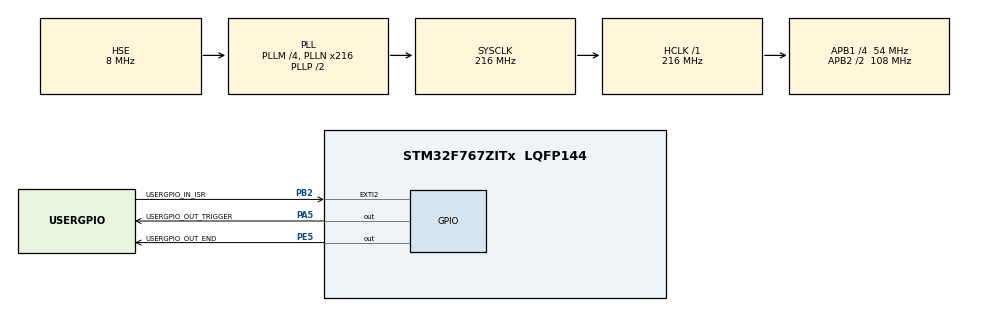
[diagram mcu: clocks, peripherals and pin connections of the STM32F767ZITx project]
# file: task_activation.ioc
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CORTEX_M7.ART_ACCELERATOR_ENABLE=0
CORTEX_M7.FlashInterface=TCM_Enabled
CORTEX_M7.PREFETCH_ENABLE=0
FREERTOS.BinarySemaphores01=semaphore,Dynamic,NULL
FREERTOS.Tasks01=Init,2,128,init,Default,NULL,Dynamic,NULL,NULL;_task1,0,128,task1,Default,NULL,Dynamic,NULL,NULL;_task2,1,128,task2,Default,NULL,Dynamic,NULL,NULL
Mcu.Family=STM32F7
Mcu.Name=STM32F767ZITx
Mcu.Package=LQFP144
NVIC.EXTI2_IRQn=true\:5\:0\:false\:false\:true\:true\:true\:true\:true
NVIC.PriorityGroup=NVIC_PRIORITYGROUP_4
NVIC.TIM6_DAC_IRQn=true\:15\:0\:false\:false\:true\:false\:false\:true\:true
NVIC.TimeBase=TIM6_DAC_IRQn
NVIC.TimeBaseIP=TIM6
PA13.GPIO_Label=TMS
PA13.Mode=Serial_Wire
PA13.Signal=SYS_JTMS-SWDIO
PA14.GPIO_Label=TCK
PA14.Mode=Serial_Wire
PA14.Signal=SYS_JTCK-SWCLK
PA5.GPIO_Label=USERGPIO_OUT_TRIGGER
PA5.GPIO_PuPd=GPIO_PULLDOWN
PA5.GPIO_Speed=GPIO_SPEED_FREQ_VERY_HIGH
PA5.Signal=GPIO_Output
PB2.GPIO_Label=USERGPIO_IN_ISR
PB2.Signal=GPXTI2
PE5.GPIO_Label=USERGPIO_OUT_END
PE5.GPIO_ModeDefaultOutputPP=GPIO_MODE_OUTPUT_PP
PE5.GPIO_PuPd=GPIO_PULLDOWN
PE5.GPIO_Speed=GPIO_SPEED_FREQ_VERY_HIGH
PE5.PinState=GPIO_PIN_RESET
PE5.Signal=GPIO_Output
PH0/OSC_IN.Mode=HSE-External-Oscillator
PH0/OSC_IN.Signal=RCC_OSC_IN
PH1/OSC_OUT.Mode=HSE-External-Oscillator
PH1/OSC_OUT.Signal=RCC_OSC_OUT
ProjectManager.HeapSize=0x200
ProjectManager.StackSize=0x400
ProjectManager.TargetToolchain=STM32CubeIDE
RCC.48MHZClocksFreq_Value=24000000
RCC.AHBFreq_Value=216000000
RCC.APB1CLKDivider=RCC_HCLK_DIV4
RCC.APB1Freq_Value=54000000
RCC.APB1TimFreq_Value=108000000
RCC.APB2CLKDivider=RCC_HCLK_DIV2
RCC.APB2Freq_Value=108000000
RCC.APB2TimFreq_Value=216000000
RCC.CortexFreq_Value=216000000
RCC.HCLKFreq_Value=216000000
RCC.HSE_VALUE=8000000
RCC.HSI_VALUE=16000000
RCC.LSE_VALUE=32768
RCC.PLLM=4
RCC.PLLMUL=RCC_PLL_MUL9
RCC.PLLN=216
RCC.PLLQ=9
RCC.PLLSourceVirtual=RCC_PLLSOURCE_HSE
RCC.PRESCALERUSB=RCC_USBCLKSOURCE_PLL_DIV1_5
RCC.SYSCLKFreq_VALUE=216000000
RCC.SYSCLKSource=RCC_SYSCLKSOURCE_PLLCLK
RCC.SYSCLKSourceVirtual=RCC_SYSCLKSOURCE_PLLCLK
RCC.USBFreq_Value=48000000
RCC.VCOOutputFreq_Value=432000000
VP_FREERTOS_VS_CMSIS_V1.Mode=CMSIS_V1
VP_SYS_VS_tim6.Mode=TIM6
board=NUCLEO-F767ZI

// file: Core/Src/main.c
/* USER CODE BEGIN Header */
/**
  ******************************************************************************
  * @file           : main.c
  * @brief          : Main program body
  ******************************************************************************
  * @attention
  *
  * Copyright (c) 2022 STMicroelectronics.
  * All rights reserved.
  *
  * This software is licensed under terms that can be found in the LICENSE file
  * in the root directory of this software component.
  * If no LICENSE file comes with this software, it is provided AS-IS.
  *
  ******************************************************************************
  */
/* USER CODE END Header */
#include "main.h"
#include "cmsis_os.h"

/* USER CODE BEGIN Includes */
#include "stdio.h"
#include <stdbool.h>
#include "FreeRTOS.h"

/* USER CODE END Includes */

/* USER CODE BEGIN PM */
#define TAKE_MEASUREMENT(x)     (x = DWT->CYCCNT)
#define NUM_SAMPLES             (1000)
/* USER CODE END PM */

osThreadId InitHandle;
osThreadId _task1Handle;
osThreadId _task2Handle;
osSemaphoreId semaphoreHandle;

void SystemClock_Config(void);
static void MX_GPIO_Init(void);
void init(void const * argument);
void task1(void const * argument);
void task2(void const * argument);

/* USER CODE BEGIN PFP */
void DWT_Init();
/* USER CODE END PFP */

/* USER CODE BEGIN 0 */
int _write(int file, char *ptr, int len)
{
    for(int i = 0 ; i < len ; ++i)
    {
        ITM_SendChar((*ptr++));
    }

    return len;
}

/* GPIO ISR callback function */
void HAL_GPIO_EXTI_Callback(uint16_t GPIO_Pin)
{
    static BaseType_t xHigherPriorityTaskWoken = pdFALSE;

    if (GPIO_Pin == USERGPIO_IN_ISR_Pin)
    {

        // xSemaphoreGiveFromISR(semaphoreISRHandle, &xHigherPriorityTaskWoken);
        vTaskNotifyGiveFromISR(_task2Handle, &xHigherPriorityTaskWoken);
        portYIELD_FROM_ISR(xHigherPriorityTaskWoken);
    }
}
/* USER CODE END 0 */

int main(void)
{

  /* MCU Configuration--------------------------------------------------------*/

  /* Reset of all peripherals, Initializes the Flash interface and the Systick. */
  HAL_Init();

  /* Configure the system clock */
  SystemClock_Config();

  /* USER CODE BEGIN SysInit */
  DWT_Init();

  /* USER CODE END SysInit */

  /* Initialize all configured peripherals */
  MX_GPIO_Init();

  /* Create the semaphores(s) */
  /* definition and creation of semaphore */
  osSemaphoreDef(semaphore);
  semaphoreHandle = osSemaphoreCreate(osSemaphore(semaphore), 1);

  /* Create the thread(s) */
  /* definition and creation of Init */
  osThreadDef(Init, init, osPriorityHigh, 0, 128);
  InitHandle = osThreadCreate(osThread(Init), NULL);

  /* definition and creation of _task1 */
  osThreadDef(_task1, task1, osPriorityNormal, 0, 128);
  _task1Handle = osThreadCreate(osThread(_task1), NULL);

  /* definition and creation of _task2 */
  osThreadDef(_task2, task2, osPriorityAboveNormal, 0, 128);
  _task2Handle = osThreadCreate(osThread(_task2), NULL);

  /* Start scheduler */
  osKernelStart();

  /* We should never get here as control is now taken by the scheduler */
  /* Infinite loop */
    while (1)
    {

    }
}

void SystemClock_Config(void)
{
  RCC_OscInitTypeDef RCC_OscInitStruct = {0};
  RCC_ClkInitTypeDef RCC_ClkInitStruct = {0};

  /** Configure the main internal regulator output voltage
  */
  __HAL_RCC_PWR_CLK_ENABLE();
  __HAL_PWR_VOLTAGESCALING_CONFIG(PWR_REGULATOR_VOLTAGE_SCALE1);

  /** Initializes the RCC Oscillators according to the specified parameters
  * in the RCC_OscInitTypeDef structure.
  */
  RCC_OscInitStruct.OscillatorType = RCC_OSCILLATORTYPE_HSE;
  RCC_OscInitStruct.HSEState = RCC_HSE_ON;
  RCC_OscInitStruct.PLL.PLLState = RCC_PLL_ON;
  RCC_OscInitStruct.PLL.PLLSource = RCC_PLLSOURCE_HSE;
  RCC_OscInitStruct.PLL.PLLM = 4;
  RCC_OscInitStruct.PLL.PLLN = 216;
  RCC_OscInitStruct.PLL.PLLP = RCC_PLLP_DIV2;
  RCC_OscInitStruct.PLL.PLLQ = 9;
  RCC_OscInitStruct.PLL.PLLR = 2;
  if (HAL_RCC_OscConfig(&RCC_OscInitStruct) != HAL_OK)
  {
    Error_Handler();
  }

  /** Activate the Over-Drive mode
  */
  if (HAL_PWREx_EnableOverDrive() != HAL_OK)
  {
    Error_Handler();
  }

  /** Initializes the CPU, AHB and APB buses clocks
  */
  RCC_ClkInitStruct.ClockType = RCC_CLOCKTYPE_HCLK|RCC_CLOCKTYPE_SYSCLK
                              |RCC_CLOCKTYPE_PCLK1|RCC_CLOCKTYPE_PCLK2;
  RCC_ClkInitStruct.SYSCLKSource = RCC_SYSCLKSOURCE_PLLCLK;
  RCC_ClkInitStruct.AHBCLKDivider = RCC_SYSCLK_DIV1;
  RCC_ClkInitStruct.APB1CLKDivider = RCC_HCLK_DIV4;
  RCC_ClkInitStruct.APB2CLKDivider = RCC_HCLK_DIV2;

  if (HAL_RCC_ClockConfig(&RCC_ClkInitStruct, FLASH_LATENCY_7) != HAL_OK)
  {
    Error_Handler();
  }
}

static void MX_GPIO_Init(void)
{
  GPIO_InitTypeDef GPIO_InitStruct = {0};

  /* GPIO Ports Clock Enable */
  __HAL_RCC_GPIOE_CLK_ENABLE();
  __HAL_RCC_GPIOH_CLK_ENABLE();
  __HAL_RCC_GPIOA_CLK_ENABLE();
  __HAL_RCC_GPIOB_CLK_ENABLE();

  /*Configure GPIO pin Output Level */
  HAL_GPIO_WritePin(USERGPIO_OUT_END_GPIO_Port, USERGPIO_OUT_END_Pin, GPIO_PIN_RESET);

  /*Configure GPIO pin Output Level */
  HAL_GPIO_WritePin(USERGPIO_OUT_TRIGGER_GPIO_Port, USERGPIO_OUT_TRIGGER_Pin, GPIO_PIN_RESET);

  /*Configure GPIO pin : USERGPIO_OUT_END_Pin */
  GPIO_InitStruct.Pin = USERGPIO_OUT_END_Pin;
  GPIO_InitStruct.Mode = GPIO_MODE_OUTPUT_PP;
  GPIO_InitStruct.Pull = GPIO_PULLDOWN;
  GPIO_InitStruct.Speed = GPIO_SPEED_FREQ_VERY_HIGH;
  HAL_GPIO_Init(USERGPIO_OUT_END_GPIO_Port, &GPIO_InitStruct);

  /*Configure GPIO pin : USERGPIO_OUT_TRIGGER_Pin */
  GPIO_InitStruct.Pin = USERGPIO_OUT_TRIGGER_Pin;
  GPIO_InitStruct.Mode = GPIO_MODE_OUTPUT_PP;
  GPIO_InitStruct.Pull = GPIO_PULLDOWN;
  GPIO_InitStruct.Speed = GPIO_SPEED_FREQ_VERY_HIGH;
  HAL_GPIO_Init(USERGPIO_OUT_TRIGGER_GPIO_Port, &GPIO_InitStruct);

  /*Configure GPIO pin : USERGPIO_IN_ISR_Pin */
  GPIO_InitStruct.Pin = USERGPIO_IN_ISR_Pin;
  GPIO_InitStruct.Mode = GPIO_MODE_IT_RISING;
  GPIO_InitStruct.Pull = GPIO_NOPULL;
  HAL_GPIO_Init(USERGPIO_IN_ISR_GPIO_Port, &GPIO_InitStruct);

  /* EXTI interrupt init*/
  HAL_NVIC_SetPriority(EXTI2_IRQn, 5, 0);
  HAL_NVIC_EnableIRQ(EXTI2_IRQn);

}

/* USER CODE BEGIN 4 */
void DWT_Init()
{
    CoreDebug->DEMCR    |= CoreDebug_DEMCR_TRCENA_Msk;  // enable DWT
    DWT->CYCCNT         =  0;	                        // set counter to 0
    DWT->CTRL           |= DWT_CTRL_CYCCNTENA_Msk;      // enable the cycle counter
}
/* USER CODE END 4 */

void init(void const * argument)
{
  /* USER CODE BEGIN 5 */
    /* Set the initial state of output pins */
    HAL_GPIO_WritePin(USERGPIO_OUT_TRIGGER_GPIO_Port, USERGPIO_OUT_TRIGGER_Pin,
                        GPIO_PIN_RESET);

    HAL_GPIO_WritePin(USERGPIO_OUT_END_GPIO_Port, USERGPIO_OUT_END_Pin,
                        GPIO_PIN_RESET);

    xSemaphoreTake(semaphoreHandle, 1);
    UBaseType_t priority = uxTaskPriorityGet(_task1Handle);
    vTaskPrioritySet(InitHandle, priority - 1);

    // printf("------------ Task activation test ------------\n");
    // printf("Check the oscilloscope for output.\n");
    // printf("Done.\n");

    while (true)
    {
        /* do nothing */
    }
  /* USER CODE END 5 */
}

void task1(void const * argument)
{
  /* USER CODE BEGIN task1 */
    for (size_t i = 0; i < NUM_SAMPLES; ++i)
    {
        xSemaphoreTake(semaphoreHandle, portMAX_DELAY);
        HAL_GPIO_WritePin(USERGPIO_OUT_TRIGGER_GPIO_Port,
                          USERGPIO_OUT_TRIGGER_Pin, GPIO_PIN_SET);
    }
  /* USER CODE END task1 */
}

void task2(void const * argument)
{
  /* USER CODE BEGIN task2 */
    const uint32_t msDelay = 200;

    for (size_t i = 0; i < NUM_SAMPLES; ++i)
    {
        /* Let task 1 run soon */
        xSemaphoreGive(semaphoreHandle);

        /* Wait for notification from ISR and set pin */
        // xSemaphoreTake(semaphoreISRHandle, portMAX_DELAY);
        xTaskNotifyWait(0xFFFFFFFF, 0xFFFFFFFF, NULL, portMAX_DELAY);
        HAL_GPIO_WritePin(USERGPIO_OUT_END_GPIO_Port, USERGPIO_OUT_END_Pin,
                          GPIO_PIN_SET);

        HAL_Delay(msDelay);
        HAL_GPIO_WritePin(USERGPIO_OUT_END_GPIO_Port, USERGPIO_OUT_END_Pin,
                          GPIO_PIN_RESET);

        HAL_GPIO_WritePin(USERGPIO_OUT_TRIGGER_GPIO_Port,
                          USERGPIO_OUT_TRIGGER_Pin, GPIO_PIN_RESET);

        HAL_Delay(msDelay);
    }
  /* USER CODE END task2 */
}

void HAL_TIM_PeriodElapsedCallback(TIM_HandleTypeDef *htim)
{
  if (htim->Instance == TIM6) {
    HAL_IncTick();
  }
}

void Error_Handler(void)
{
  __disable_irq();
  while (1)
  {
  }
}
